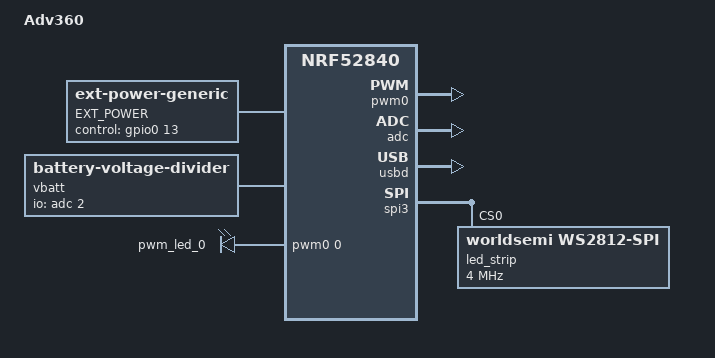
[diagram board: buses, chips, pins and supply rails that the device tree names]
/*
*
* Copyright (c) 2021 Polarity Works
* SPDX-License-Identifier: MIT
*
*/

/dts-v1/;
#include <nordic/nrf52840_qiaa.dtsi>

#include <dt-bindings/led/led.h>
#include <dt-bindings/zmk/matrix_transform.h>

#include "adv360-layouts.dtsi"
#include "adv360_pinctrl.dtsi"

&physical_layout0 {
    transform = <&matrix_transform0>;
};

/ {
    model = "Adv360";
    compatible = "kinesis,adv360";

    chosen {
        zephyr,code-partition = &code_partition;
        zephyr,sram = &sram0;
        zephyr,flash = &flash0;
        zmk,kscan = &kscan0;
        zmk,backlight = &backlight;
        zmk,battery = &vbatt;
        zmk,physical-layout = &physical_layout0;
        zmk,underglow = &led_strip;
    };

    matrix_transform0: keymap_transform_0 {
        compatible = "zmk,matrix-transform";
        columns = <64>;
        rows = <37>;


                    map = <
            RC(4,0) RC(4,1) RC(4,2) RC(4,3) RC(4,4) RC(4,5)  RC(4,6)                                                                        RC(4,13) RC(4,14) RC(4,15) RC(4,16) RC(4,17) RC(4,18) RC(4,19)
            RC(3,0) RC(3,1) RC(3,2) RC(3,3) RC(3,4) RC(3,5)  RC(3,6)                                                                        RC(3,13) RC(3,14) RC(3,15) RC(3,16) RC(3,17) RC(3,18) RC(3,19)
            RC(2,0) RC(2,1) RC(2,2) RC(2,3) RC(2,4) RC(2,5)  RC(2,6)           RC(2,8)  RC(2,9)            RC(2,10) RC(2,11)                RC(2,13) RC(2,14) RC(2,15) RC(2,16) RC(2,17) RC(2,18) RC(2,19)
            RC(1,0) RC(1,1) RC(1,2) RC(1,3) RC(1,4) RC(1,5)                             RC(1,9)            RC(1,10)                                  RC(1,14) RC(1,15) RC(1,16) RC(1,17) RC(1,18) RC(1,19)
            RC(0,0) RC(0,1) RC(0,2) RC(0,3) RC(0,4)                     RC(0,7) RC(0,8) RC(0,9)            RC(0,10) RC(0,11) RC(0,12)                         RC(0,15) RC(0,16) RC(0,17) RC(0,18) RC(0,19)



RC(5,0) RC(5,1) RC(5,2) RC(5,3) RC(5,4) RC(5,5) RC(5,6) RC(5,7) RC(5,8) RC(5,9) RC(5,10) RC(5,11) RC(5,12) RC(5,13) RC(5,14) RC(5,15) RC(5,16) RC(5,17) RC(5,18) RC(5,19) RC(5,20) RC(5,21) RC(5,22) RC(5,23) RC(5,24) RC(5,25) RC(5,26) RC(5,27) RC(5,28) RC(5,29) RC(5,30) RC(5,31) RC(5,32) RC(5,33) RC(5,34) RC(5,35) RC(5,36) RC(5,37) RC(5,38) RC(5,39) RC(5,40) RC(5,41) RC(5,42) RC(5,43) RC(5,44) RC(5,45) RC(5,46) RC(5,47) RC(5,48) RC(5,49) RC(5,50) RC(5,51) RC(5,52) RC(5,53) RC(5,54) RC(5,55) RC(5,56) RC(5,57) RC(5,58) RC(5,59) RC(5,60) RC(5,61) RC(5,62) RC(5,63) 
RC(6,0) RC(6,1) RC(6,2) RC(6,3) RC(6,4) RC(6,5) RC(6,6) RC(6,7) RC(6,8) RC(6,9) RC(6,10) RC(6,11) RC(6,12) RC(6,13) RC(6,14) RC(6,15) RC(6,16) RC(6,17) RC(6,18) RC(6,19) RC(6,20) RC(6,21) RC(6,22) RC(6,23) RC(6,24) RC(6,25) RC(6,26) RC(6,27) RC(6,28) RC(6,29) RC(6,30) RC(6,31) RC(6,32) RC(6,33) RC(6,34) RC(6,35) RC(6,36) RC(6,37) RC(6,38) RC(6,39) RC(6,40) RC(6,41) RC(6,42) RC(6,43) RC(6,44) RC(6,45) RC(6,46) RC(6,47) RC(6,48) RC(6,49) RC(6,50) RC(6,51) RC(6,52) RC(6,53) RC(6,54) RC(6,55) RC(6,56) RC(6,57) RC(6,58) RC(6,59) RC(6,60) RC(6,61) RC(6,62) RC(6,63) 
RC(7,0) RC(7,1) RC(7,2) RC(7,3) RC(7,4) RC(7,5) RC(7,6) RC(7,7) RC(7,8) RC(7,9) RC(7,10) RC(7,11) RC(7,12) RC(7,13) RC(7,14) RC(7,15) RC(7,16) RC(7,17) RC(7,18) RC(7,19) RC(7,20) RC(7,21) RC(7,22) RC(7,23) RC(7,24) RC(7,25) RC(7,26) RC(7,27) RC(7,28) RC(7,29) RC(7,30) RC(7,31) RC(7,32) RC(7,33) RC(7,34) RC(7,35) RC(7,36) RC(7,37) RC(7,38) RC(7,39) RC(7,40) RC(7,41) RC(7,42) RC(7,43) RC(7,44) RC(7,45) RC(7,46) RC(7,47) RC(7,48) RC(7,49) RC(7,50) RC(7,51) RC(7,52) RC(7,53) RC(7,54) RC(7,55) RC(7,56) RC(7,57) RC(7,58) RC(7,59) RC(7,60) RC(7,61) RC(7,62) RC(7,63) 
RC(8,0) RC(8,1) RC(8,2) RC(8,3) RC(8,4) RC(8,5) RC(8,6) RC(8,7) RC(8,8) RC(8,9) RC(8,10) RC(8,11) RC(8,12) RC(8,13) RC(8,14) RC(8,15) RC(8,16) RC(8,17) RC(8,18) RC(8,19) RC(8,20) RC(8,21) RC(8,22) RC(8,23) RC(8,24) RC(8,25) RC(8,26) RC(8,27) RC(8,28) RC(8,29) RC(8,30) RC(8,31) RC(8,32) RC(8,33) RC(8,34) RC(8,35) RC(8,36) RC(8,37) RC(8,38) RC(8,39) RC(8,40) RC(8,41) RC(8,42) RC(8,43) RC(8,44) RC(8,45) RC(8,46) RC(8,47) RC(8,48) RC(8,49) RC(8,50) RC(8,51) RC(8,52) RC(8,53) RC(8,54) RC(8,55) RC(8,56) RC(8,57) RC(8,58) RC(8,59) RC(8,60) RC(8,61) RC(8,62) RC(8,63) 
RC(9,0) RC(9,1) RC(9,2) RC(9,3) RC(9,4) RC(9,5) RC(9,6) RC(9,7) RC(9,8) RC(9,9) RC(9,10) RC(9,11) RC(9,12) RC(9,13) RC(9,14) RC(9,15) RC(9,16) RC(9,17) RC(9,18) RC(9,19) RC(9,20) RC(9,21) RC(9,22) RC(9,23) RC(9,24) RC(9,25) RC(9,26) RC(9,27) RC(9,28) RC(9,29) RC(9,30) RC(9,31) RC(9,32) RC(9,33) RC(9,34) RC(9,35) RC(9,36) RC(9,37) RC(9,38) RC(9,39) RC(9,40) RC(9,41) RC(9,42) RC(9,43) RC(9,44) RC(9,45) RC(9,46) RC(9,47) RC(9,48) RC(9,49) RC(9,50) RC(9,51) RC(9,52) RC(9,53) RC(9,54) RC(9,55) RC(9,56) RC(9,57) RC(9,58) RC(9,59) RC(9,60) RC(9,61) RC(9,62) RC(9,63) 
RC(10,0) RC(10,1) RC(10,2) RC(10,3) RC(10,4) RC(10,5) RC(10,6) RC(10,7) RC(10,8) RC(10,9) RC(10,10) RC(10,11) RC(10,12) RC(10,13) RC(10,14) RC(10,15) RC(10,16) RC(10,17) RC(10,18) RC(10,19) RC(10,20) RC(10,21) RC(10,22) RC(10,23) RC(10,24) RC(10,25) RC(10,26) RC(10,27) RC(10,28) RC(10,29) RC(10,30) RC(10,31) RC(10,32) RC(10,33) RC(10,34) RC(10,35) RC(10,36) RC(10,37) RC(10,38) RC(10,39) RC(10,40) RC(10,41) RC(10,42) RC(10,43) RC(10,44) RC(10,45) RC(10,46) RC(10,47) RC(10,48) RC(10,49) RC(10,50) RC(10,51) RC(10,52) RC(10,53) RC(10,54) RC(10,55) RC(10,56) RC(10,57) RC(10,58) RC(10,59) RC(10,60) RC(10,61) RC(10,62) RC(10,63) 
RC(11,0) RC(11,1) RC(11,2) RC(11,3) RC(11,4) RC(11,5) RC(11,6) RC(11,7) RC(11,8) RC(11,9) RC(11,10) RC(11,11) RC(11,12) RC(11,13) RC(11,14) RC(11,15) RC(11,16) RC(11,17) RC(11,18) RC(11,19) RC(11,20) RC(11,21) RC(11,22) RC(11,23) RC(11,24) RC(11,25) RC(11,26) RC(11,27) RC(11,28) RC(11,29) RC(11,30) RC(11,31) RC(11,32) RC(11,33) RC(11,34) RC(11,35) RC(11,36) RC(11,37) RC(11,38) RC(11,39) RC(11,40) RC(11,41) RC(11,42) RC(11,43) RC(11,44) RC(11,45) RC(11,46) RC(11,47) RC(11,48) RC(11,49) RC(11,50) RC(11,51) RC(11,52) RC(11,53) RC(11,54) RC(11,55) RC(11,56) RC(11,57) RC(11,58) RC(11,59) RC(11,60) RC(11,61) RC(11,62) RC(11,63) 
RC(12,0) RC(12,1) RC(12,2) RC(12,3) RC(12,4) RC(12,5) RC(12,6) RC(12,7) RC(12,8) RC(12,9) RC(12,10) RC(12,11) RC(12,12) RC(12,13) RC(12,14) RC(12,15) RC(12,16) RC(12,17) RC(12,18) RC(12,19) RC(12,20) RC(12,21) RC(12,22) RC(12,23) RC(12,24) RC(12,25) RC(12,26) RC(12,27) RC(12,28) RC(12,29) RC(12,30) RC(12,31) RC(12,32) RC(12,33) RC(12,34) RC(12,35) RC(12,36) RC(12,37) RC(12,38) RC(12,39) RC(12,40) RC(12,41) RC(12,42) RC(12,43) RC(12,44) RC(12,45) RC(12,46) RC(12,47) RC(12,48) RC(12,49) RC(12,50) RC(12,51) RC(12,52) RC(12,53) RC(12,54) RC(12,55) RC(12,56) RC(12,57) RC(12,58) RC(12,59) RC(12,60) RC(12,61) RC(12,62) RC(12,63) 
RC(13,0) RC(13,1) RC(13,2) RC(13,3) RC(13,4) RC(13,5) RC(13,6) RC(13,7) RC(13,8) RC(13,9) RC(13,10) RC(13,11) RC(13,12) RC(13,13) RC(13,14) RC(13,15) RC(13,16) RC(13,17) RC(13,18) RC(13,19) RC(13,20) RC(13,21) RC(13,22) RC(13,23) RC(13,24) RC(13,25) RC(13,26) RC(13,27) RC(13,28) RC(13,29) RC(13,30) RC(13,31) RC(13,32) RC(13,33) RC(13,34) RC(13,35) RC(13,36) RC(13,37) RC(13,38) RC(13,39) RC(13,40) RC(13,41) RC(13,42) RC(13,43) RC(13,44) RC(13,45) RC(13,46) RC(13,47) RC(13,48) RC(13,49) RC(13,50) RC(13,51) RC(13,52) RC(13,53) RC(13,54) RC(13,55) RC(13,56) RC(13,57) RC(13,58) RC(13,59) RC(13,60) RC(13,61) RC(13,62) RC(13,63) 
RC(14,0) RC(14,1) RC(14,2) RC(14,3) RC(14,4) RC(14,5) RC(14,6) RC(14,7) RC(14,8) RC(14,9) RC(14,10) RC(14,11) RC(14,12) RC(14,13) RC(14,14) RC(14,15) RC(14,16) RC(14,17) RC(14,18) RC(14,19) RC(14,20) RC(14,21) RC(14,22) RC(14,23) RC(14,24) RC(14,25) RC(14,26) RC(14,27) RC(14,28) RC(14,29) RC(14,30) RC(14,31) RC(14,32) RC(14,33) RC(14,34) RC(14,35) RC(14,36) RC(14,37) RC(14,38) RC(14,39) RC(14,40) RC(14,41) RC(14,42) RC(14,43) RC(14,44) RC(14,45) RC(14,46) RC(14,47) RC(14,48) RC(14,49) RC(14,50) RC(14,51) RC(14,52) RC(14,53) RC(14,54) RC(14,55) RC(14,56) RC(14,57) RC(14,58) RC(14,59) RC(14,60) RC(14,61) RC(14,62) RC(14,63) 
RC(15,0) RC(15,1) RC(15,2) RC(15,3) RC(15,4) RC(15,5) RC(15,6) RC(15,7) RC(15,8) RC(15,9) RC(15,10) RC(15,11) RC(15,12) RC(15,13) RC(15,14) RC(15,15) RC(15,16) RC(15,17) RC(15,18) RC(15,19) RC(15,20) RC(15,21) RC(15,22) RC(15,23) RC(15,24) RC(15,25) RC(15,26) RC(15,27) RC(15,28) RC(15,29) RC(15,30) RC(15,31) RC(15,32) RC(15,33) RC(15,34) RC(15,35) RC(15,36) RC(15,37) RC(15,38) RC(15,39) RC(15,40) RC(15,41) RC(15,42) RC(15,43) RC(15,44) RC(15,45) RC(15,46) RC(15,47) RC(15,48) RC(15,49) RC(15,50) RC(15,51) RC(15,52) RC(15,53) RC(15,54) RC(15,55) RC(15,56) RC(15,57) RC(15,58) RC(15,59) RC(15,60) RC(15,61) RC(15,62) RC(15,63) 
RC(16,0) RC(16,1) RC(16,2) RC(16,3) RC(16,4) RC(16,5) RC(16,6) RC(16,7) RC(16,8) RC(16,9) RC(16,10) RC(16,11) RC(16,12) RC(16,13) RC(16,14) RC(16,15) RC(16,16) RC(16,17) RC(16,18) RC(16,19) RC(16,20) RC(16,21) RC(16,22) RC(16,23) RC(16,24) RC(16,25) RC(16,26) RC(16,27) RC(16,28) RC(16,29) RC(16,30) RC(16,31) RC(16,32) RC(16,33) RC(16,34) RC(16,35) RC(16,36) RC(16,37) RC(16,38) RC(16,39) RC(16,40) RC(16,41) RC(16,42) RC(16,43) RC(16,44) RC(16,45) RC(16,46) RC(16,47) RC(16,48) RC(16,49) RC(16,50) RC(16,51) RC(16,52) RC(16,53) RC(16,54) RC(16,55) RC(16,56) RC(16,57) RC(16,58) RC(16,59) RC(16,60) RC(16,61) RC(16,62) RC(16,63) 
RC(17,0) RC(17,1) RC(17,2) RC(17,3) RC(17,4) RC(17,5) RC(17,6) RC(17,7) RC(17,8) RC(17,9) RC(17,10) RC(17,11) RC(17,12) RC(17,13) RC(17,14) RC(17,15) RC(17,16) RC(17,17) RC(17,18) RC(17,19) RC(17,20) RC(17,21) RC(17,22) RC(17,23) RC(17,24) RC(17,25) RC(17,26) RC(17,27) RC(17,28) RC(17,29) RC(17,30) RC(17,31) RC(17,32) RC(17,33) RC(17,34) RC(17,35) RC(17,36) RC(17,37) RC(17,38) RC(17,39) RC(17,40) RC(17,41) RC(17,42) RC(17,43) RC(17,44) RC(17,45) RC(17,46) RC(17,47) RC(17,48) RC(17,49) RC(17,50) RC(17,51) RC(17,52) RC(17,53) RC(17,54) RC(17,55) RC(17,56) RC(17,57) RC(17,58) RC(17,59) RC(17,60) RC(17,61) RC(17,62) RC(17,63) 
RC(18,0) RC(18,1) RC(18,2) RC(18,3) RC(18,4) RC(18,5) RC(18,6) RC(18,7) RC(18,8) RC(18,9) RC(18,10) RC(18,11) RC(18,12) RC(18,13) RC(18,14) RC(18,15) RC(18,16) RC(18,17) RC(18,18) RC(18,19) RC(18,20) RC(18,21) RC(18,22) RC(18,23) RC(18,24) RC(18,25) RC(18,26) RC(18,27) RC(18,28) RC(18,29) RC(18,30) RC(18,31) RC(18,32) RC(18,33) RC(18,34) RC(18,35) RC(18,36) RC(18,37) RC(18,38) RC(18,39) RC(18,40) RC(18,41) RC(18,42) RC(18,43) RC(18,44) RC(18,45) RC(18,46) RC(18,47) RC(18,48) RC(18,49) RC(18,50) RC(18,51) RC(18,52) RC(18,53) RC(18,54) RC(18,55) RC(18,56) RC(18,57) RC(18,58) RC(18,59) RC(18,60) RC(18,61) RC(18,62) RC(18,63) 
RC(19,0) RC(19,1) RC(19,2) RC(19,3) RC(19,4) RC(19,5) RC(19,6) RC(19,7) RC(19,8) RC(19,9) RC(19,10) RC(19,11) RC(19,12) RC(19,13) RC(19,14) RC(19,15) RC(19,16) RC(19,17) RC(19,18) RC(19,19) RC(19,20) RC(19,21) RC(19,22) RC(19,23) RC(19,24) RC(19,25) RC(19,26) RC(19,27) RC(19,28) RC(19,29) RC(19,30) RC(19,31) RC(19,32) RC(19,33) RC(19,34) RC(19,35) RC(19,36) RC(19,37) RC(19,38) RC(19,39) RC(19,40) RC(19,41) RC(19,42) RC(19,43) RC(19,44) RC(19,45) RC(19,46) RC(19,47) RC(19,48) RC(19,49) RC(19,50) RC(19,51) RC(19,52) RC(19,53) RC(19,54) RC(19,55) RC(19,56) RC(19,57) RC(19,58) RC(19,59) RC(19,60) RC(19,61) RC(19,62) RC(19,63) 
RC(20,0) RC(20,1) RC(20,2) RC(20,3) RC(20,4) RC(20,5) RC(20,6) RC(20,7) RC(20,8) RC(20,9) RC(20,10) RC(20,11) RC(20,12) RC(20,13) RC(20,14) RC(20,15) RC(20,16) RC(20,17) RC(20,18) RC(20,19) RC(20,20) RC(20,21) RC(20,22) RC(20,23) RC(20,24) RC(20,25) RC(20,26) RC(20,27) RC(20,28) RC(20,29) RC(20,30) RC(20,31) RC(20,32) RC(20,33) RC(20,34) RC(20,35) RC(20,36) RC(20,37) RC(20,38) RC(20,39) RC(20,40) RC(20,41) RC(20,42) RC(20,43) RC(20,44) RC(20,45) RC(20,46) RC(20,47) RC(20,48) RC(20,49) RC(20,50) RC(20,51) RC(20,52) RC(20,53) RC(20,54) RC(20,55) RC(20,56) RC(20,57) RC(20,58) RC(20,59) RC(20,60) RC(20,61) RC(20,62) RC(20,63) 
RC(21,0) RC(21,1) RC(21,2) RC(21,3) RC(21,4) RC(21,5) RC(21,6) RC(21,7) RC(21,8) RC(21,9) RC(21,10) RC(21,11) RC(21,12) RC(21,13) RC(21,14) RC(21,15) RC(21,16) RC(21,17) RC(21,18) RC(21,19) RC(21,20) RC(21,21) RC(21,22) RC(21,23) RC(21,24) RC(21,25) RC(21,26) RC(21,27) RC(21,28) RC(21,29) RC(21,30) RC(21,31) RC(21,32) RC(21,33) RC(21,34) RC(21,35) RC(21,36) RC(21,37) RC(21,38) RC(21,39) RC(21,40) RC(21,41) RC(21,42) RC(21,43) RC(21,44) RC(21,45) RC(21,46) RC(21,47) RC(21,48) RC(21,49) RC(21,50) RC(21,51) RC(21,52) RC(21,53) RC(21,54) RC(21,55) RC(21,56) RC(21,57) RC(21,58) RC(21,59) RC(21,60) RC(21,61) RC(21,62) RC(21,63) 
RC(22,0) RC(22,1) RC(22,2) RC(22,3) RC(22,4) RC(22,5) RC(22,6) RC(22,7) RC(22,8) RC(22,9) RC(22,10) RC(22,11) RC(22,12) RC(22,13) RC(22,14) RC(22,15) RC(22,16) RC(22,17) RC(22,18) RC(22,19) RC(22,20) RC(22,21) RC(22,22) RC(22,23) RC(22,24) RC(22,25) RC(22,26) RC(22,27) RC(22,28) RC(22,29) RC(22,30) RC(22,31) RC(22,32) RC(22,33) RC(22,34) RC(22,35) RC(22,36) RC(22,37) RC(22,38) RC(22,39) RC(22,40) RC(22,41) RC(22,42) RC(22,43) RC(22,44) RC(22,45) RC(22,46) RC(22,47) RC(22,48) RC(22,49) RC(22,50) RC(22,51) RC(22,52) RC(22,53) RC(22,54) RC(22,55) RC(22,56) RC(22,57) RC(22,58) RC(22,59) RC(22,60) RC(22,61) RC(22,62) RC(22,63) 
RC(23,0) RC(23,1) RC(23,2) RC(23,3) RC(23,4) RC(23,5) RC(23,6) RC(23,7) RC(23,8) RC(23,9) RC(23,10) RC(23,11) RC(23,12) RC(23,13) RC(23,14) RC(23,15) RC(23,16) RC(23,17) RC(23,18) RC(23,19) RC(23,20) RC(23,21) RC(23,22) RC(23,23) RC(23,24) RC(23,25) RC(23,26) RC(23,27) RC(23,28) RC(23,29) RC(23,30) RC(23,31) RC(23,32) RC(23,33) RC(23,34) RC(23,35) RC(23,36) RC(23,37) RC(23,38) RC(23,39) RC(23,40) RC(23,41) RC(23,42) RC(23,43) RC(23,44) RC(23,45) RC(23,46) RC(23,47) RC(23,48) RC(23,49) RC(23,50) RC(23,51) RC(23,52) RC(23,53) RC(23,54) RC(23,55) RC(23,56) RC(23,57) RC(23,58) RC(23,59) RC(23,60) RC(23,61) RC(23,62) RC(23,63) 
RC(24,0) RC(24,1) RC(24,2) RC(24,3) RC(24,4) RC(24,5) RC(24,6) RC(24,7) RC(24,8) RC(24,9) RC(24,10) RC(24,11) RC(24,12) RC(24,13) RC(24,14) RC(24,15) RC(24,16) RC(24,17) RC(24,18) RC(24,19) RC(24,20) RC(24,21) RC(24,22) RC(24,23) RC(24,24) RC(24,25) RC(24,26) RC(24,27) RC(24,28) RC(24,29) RC(24,30) RC(24,31) RC(24,32) RC(24,33) RC(24,34) RC(24,35) RC(24,36) RC(24,37) RC(24,38) RC(24,39) RC(24,40) RC(24,41) RC(24,42) RC(24,43) RC(24,44) RC(24,45) RC(24,46) RC(24,47) RC(24,48) RC(24,49) RC(24,50) RC(24,51) RC(24,52) RC(24,53) RC(24,54) RC(24,55) RC(24,56) RC(24,57) RC(24,58) RC(24,59) RC(24,60) RC(24,61) RC(24,62) RC(24,63) 
RC(25,0) RC(25,1) RC(25,2) RC(25,3) RC(25,4) RC(25,5) RC(25,6) RC(25,7) RC(25,8) RC(25,9) RC(25,10) RC(25,11) RC(25,12) RC(25,13) RC(25,14) RC(25,15) RC(25,16) RC(25,17) RC(25,18) RC(25,19) RC(25,20) RC(25,21) RC(25,22) RC(25,23) RC(25,24) RC(25,25) RC(25,26) RC(25,27) RC(25,28) RC(25,29) RC(25,30) RC(25,31) RC(25,32) RC(25,33) RC(25,34) RC(25,35) RC(25,36) RC(25,37) RC(25,38) RC(25,39) RC(25,40) RC(25,41) RC(25,42) RC(25,43) RC(25,44) RC(25,45) RC(25,46) RC(25,47) RC(25,48) RC(25,49) RC(25,50) RC(25,51) RC(25,52) RC(25,53) RC(25,54) RC(25,55) RC(25,56) RC(25,57) RC(25,58) RC(25,59) RC(25,60) RC(25,61) RC(25,62) RC(25,63) 
RC(26,0) RC(26,1) RC(26,2) RC(26,3) RC(26,4) RC(26,5) RC(26,6) RC(26,7) RC(26,8) RC(26,9) RC(26,10) RC(26,11) RC(26,12) RC(26,13) RC(26,14) RC(26,15) RC(26,16) RC(26,17) RC(26,18) RC(26,19) RC(26,20) RC(26,21) RC(26,22) RC(26,23) RC(26,24) RC(26,25) RC(26,26) RC(26,27) RC(26,28) RC(26,29) RC(26,30) RC(26,31) RC(26,32) RC(26,33) RC(26,34) RC(26,35) RC(26,36) RC(26,37) RC(26,38) RC(26,39) RC(26,40) RC(26,41) RC(26,42) RC(26,43) RC(26,44) RC(26,45) RC(26,46) RC(26,47) RC(26,48) RC(26,49) RC(26,50) RC(26,51) RC(26,52) RC(26,53) RC(26,54) RC(26,55) RC(26,56) RC(26,57) RC(26,58) RC(26,59) RC(26,60) RC(26,61) RC(26,62) RC(26,63) 
RC(27,0) RC(27,1) RC(27,2) RC(27,3) RC(27,4) RC(27,5) RC(27,6) RC(27,7) RC(27,8) RC(27,9) RC(27,10) RC(27,11) RC(27,12) RC(27,13) RC(27,14) RC(27,15) RC(27,16) RC(27,17) RC(27,18) RC(27,19) RC(27,20) RC(27,21) RC(27,22) RC(27,23) RC(27,24) RC(27,25) RC(27,26) RC(27,27) RC(27,28) RC(27,29) RC(27,30) RC(27,31) RC(27,32) RC(27,33) RC(27,34) RC(27,35) RC(27,36) RC(27,37) RC(27,38) RC(27,39) RC(27,40) RC(27,41) RC(27,42) RC(27,43) RC(27,44) RC(27,45) RC(27,46) RC(27,47) RC(27,48) RC(27,49) RC(27,50) RC(27,51) RC(27,52) RC(27,53) RC(27,54) RC(27,55) RC(27,56) RC(27,57) RC(27,58) RC(27,59) RC(27,60) RC(27,61) RC(27,62) RC(27,63) 
RC(28,0) RC(28,1) RC(28,2) RC(28,3) RC(28,4) RC(28,5) RC(28,6) RC(28,7) RC(28,8) RC(28,9) RC(28,10) RC(28,11) RC(28,12) RC(28,13) RC(28,14) RC(28,15) RC(28,16) RC(28,17) RC(28,18) RC(28,19) RC(28,20) RC(28,21) RC(28,22) RC(28,23) RC(28,24) RC(28,25) RC(28,26) RC(28,27) RC(28,28) RC(28,29) RC(28,30) RC(28,31) RC(28,32) RC(28,33) RC(28,34) RC(28,35) RC(28,36) RC(28,37) RC(28,38) RC(28,39) RC(28,40) RC(28,41) RC(28,42) RC(28,43) RC(28,44) RC(28,45) RC(28,46) RC(28,47) RC(28,48) RC(28,49) RC(28,50) RC(28,51) RC(28,52) RC(28,53) RC(28,54) RC(28,55) RC(28,56) RC(28,57) RC(28,58) RC(28,59) RC(28,60) RC(28,61) RC(28,62) RC(28,63) 
RC(29,0) RC(29,1) RC(29,2) RC(29,3) RC(29,4) RC(29,5) RC(29,6) RC(29,7) RC(29,8) RC(29,9) RC(29,10) RC(29,11) RC(29,12) RC(29,13) RC(29,14) RC(29,15) RC(29,16) RC(29,17) RC(29,18) RC(29,19) RC(29,20) RC(29,21) RC(29,22) RC(29,23) RC(29,24) RC(29,25) RC(29,26) RC(29,27) RC(29,28) RC(29,29) RC(29,30) RC(29,31) RC(29,32) RC(29,33) RC(29,34) RC(29,35) RC(29,36) RC(29,37) RC(29,38) RC(29,39) RC(29,40) RC(29,41) RC(29,42) RC(29,43) RC(29,44) RC(29,45) RC(29,46) RC(29,47) RC(29,48) RC(29,49) RC(29,50) RC(29,51) RC(29,52) RC(29,53) RC(29,54) RC(29,55) RC(29,56) RC(29,57) RC(29,58) RC(29,59) RC(29,60) RC(29,61) RC(29,62) RC(29,63) 
RC(30,0) RC(30,1) RC(30,2) RC(30,3) RC(30,4) RC(30,5) RC(30,6) RC(30,7) RC(30,8) RC(30,9) RC(30,10) RC(30,11) RC(30,12) RC(30,13) RC(30,14) RC(30,15) RC(30,16) RC(30,17) RC(30,18) RC(30,19) RC(30,20) RC(30,21) RC(30,22) RC(30,23) RC(30,24) RC(30,25) RC(30,26) RC(30,27) RC(30,28) RC(30,29) RC(30,30) RC(30,31) RC(30,32) RC(30,33) RC(30,34) RC(30,35) RC(30,36) RC(30,37) RC(30,38) RC(30,39) RC(30,40) RC(30,41) RC(30,42) RC(30,43) RC(30,44) RC(30,45) RC(30,46) RC(30,47) RC(30,48) RC(30,49) RC(30,50) RC(30,51) RC(30,52) RC(30,53) RC(30,54) RC(30,55) RC(30,56) RC(30,57) RC(30,58) RC(30,59) RC(30,60) RC(30,61) RC(30,62) RC(30,63) 
RC(31,0) RC(31,1) RC(31,2) RC(31,3) RC(31,4) RC(31,5) RC(31,6) RC(31,7) RC(31,8) RC(31,9) RC(31,10) RC(31,11) RC(31,12) RC(31,13) RC(31,14) RC(31,15) RC(31,16) RC(31,17) RC(31,18) RC(31,19) RC(31,20) RC(31,21) RC(31,22) RC(31,23) RC(31,24) RC(31,25) RC(31,26) RC(31,27) RC(31,28) RC(31,29) RC(31,30) RC(31,31) RC(31,32) RC(31,33) RC(31,34) RC(31,35) RC(31,36) RC(31,37) RC(31,38) RC(31,39) RC(31,40) RC(31,41) RC(31,42) RC(31,43) RC(31,44) RC(31,45) RC(31,46) RC(31,47) RC(31,48) RC(31,49) RC(31,50) RC(31,51) RC(31,52) RC(31,53) RC(31,54) RC(31,55) RC(31,56) RC(31,57) RC(31,58) RC(31,59) RC(31,60) RC(31,61) RC(31,62) RC(31,63) 
RC(32,0) RC(32,1) RC(32,2) RC(32,3) RC(32,4) RC(32,5) RC(32,6) RC(32,7) RC(32,8) RC(32,9) RC(32,10) RC(32,11) RC(32,12) RC(32,13) RC(32,14) RC(32,15) RC(32,16) RC(32,17) RC(32,18) RC(32,19) RC(32,20) RC(32,21) RC(32,22) RC(32,23) RC(32,24) RC(32,25) RC(32,26) RC(32,27) RC(32,28) RC(32,29) RC(32,30) RC(32,31) RC(32,32) RC(32,33) RC(32,34) RC(32,35) RC(32,36) RC(32,37) RC(32,38) RC(32,39) RC(32,40) RC(32,41) RC(32,42) RC(32,43) RC(32,44) RC(32,45) RC(32,46) RC(32,47) RC(32,48) RC(32,49) RC(32,50) RC(32,51) RC(32,52) RC(32,53) RC(32,54) RC(32,55) RC(32,56) RC(32,57) RC(32,58) RC(32,59) RC(32,60) RC(32,61) RC(32,62) RC(32,63) 
RC(33,0) RC(33,1) RC(33,2) RC(33,3) RC(33,4) RC(33,5) RC(33,6) RC(33,7) RC(33,8) RC(33,9) RC(33,10) RC(33,11) RC(33,12) RC(33,13) RC(33,14) RC(33,15) RC(33,16) RC(33,17) RC(33,18) RC(33,19) RC(33,20) RC(33,21) RC(33,22) RC(33,23) RC(33,24) RC(33,25) RC(33,26) RC(33,27) RC(33,28) RC(33,29) RC(33,30) RC(33,31) RC(33,32) RC(33,33) RC(33,34) RC(33,35) RC(33,36) RC(33,37) RC(33,38) RC(33,39) RC(33,40) RC(33,41) RC(33,42) RC(33,43) RC(33,44) RC(33,45) RC(33,46) RC(33,47) RC(33,48) RC(33,49) RC(33,50) RC(33,51) RC(33,52) RC(33,53) RC(33,54) RC(33,55) RC(33,56) RC(33,57) RC(33,58) RC(33,59) RC(33,60) RC(33,61) RC(33,62) RC(33,63) 
RC(34,0) RC(34,1) RC(34,2) RC(34,3) RC(34,4) RC(34,5) RC(34,6) RC(34,7) RC(34,8) RC(34,9) RC(34,10) RC(34,11) RC(34,12) RC(34,13) RC(34,14) RC(34,15) RC(34,16) RC(34,17) RC(34,18) RC(34,19) RC(34,20) RC(34,21) RC(34,22) RC(34,23) RC(34,24) RC(34,25) RC(34,26) RC(34,27) RC(34,28) RC(34,29) RC(34,30) RC(34,31) RC(34,32) RC(34,33) RC(34,34) RC(34,35) RC(34,36) RC(34,37) RC(34,38) RC(34,39) RC(34,40) RC(34,41) RC(34,42) RC(34,43) RC(34,44) RC(34,45) RC(34,46) RC(34,47) RC(34,48) RC(34,49) RC(34,50) RC(34,51) RC(34,52) RC(34,53) RC(34,54) RC(34,55) RC(34,56) RC(34,57) RC(34,58) RC(34,59) RC(34,60) RC(34,61) RC(34,62) RC(34,63) 
RC(35,0) RC(35,1) RC(35,2) RC(35,3) RC(35,4) RC(35,5) RC(35,6) RC(35,7) RC(35,8) RC(35,9) RC(35,10) RC(35,11) RC(35,12) RC(35,13) RC(35,14) RC(35,15) RC(35,16) RC(35,17) RC(35,18) RC(35,19) RC(35,20) RC(35,21) RC(35,22) RC(35,23) RC(35,24) RC(35,25) RC(35,26) RC(35,27) RC(35,28) RC(35,29) RC(35,30) RC(35,31) RC(35,32) RC(35,33) RC(35,34) RC(35,35) RC(35,36) RC(35,37) RC(35,38) RC(35,39) RC(35,40) RC(35,41) RC(35,42) RC(35,43) RC(35,44) RC(35,45) RC(35,46) RC(35,47) RC(35,48) RC(35,49) RC(35,50) RC(35,51) RC(35,52) RC(35,53) RC(35,54) RC(35,55) RC(35,56) RC(35,57) RC(35,58) RC(35,59) RC(35,60) RC(35,61) RC(35,62) RC(35,63) 
RC(36,0) RC(36,1) RC(36,2) RC(36,3) RC(36,4) RC(36,5) RC(36,6) RC(36,7) RC(36,8) RC(36,9) RC(36,10) RC(36,11) RC(36,12) RC(36,13) RC(36,14) RC(36,15) RC(36,16) RC(36,17) RC(36,18) RC(36,19) RC(36,20) RC(36,21) RC(36,22) RC(36,23) RC(36,24) RC(36,25) RC(36,26) RC(36,27) RC(36,28) RC(36,29) RC(36,30) RC(36,31) RC(36,32) RC(36,33) RC(36,34) RC(36,35) RC(36,36) RC(36,37) RC(36,38) RC(36,39) RC(36,40) RC(36,41) RC(36,42) RC(36,43) RC(36,44) RC(36,45) RC(36,46) RC(36,47) RC(36,48) RC(36,49) RC(36,50) RC(36,51) RC(36,52) RC(36,53) RC(36,54) RC(36,55) RC(36,56) RC(36,57) RC(36,58) RC(36,59) RC(36,60) RC(36,61) RC(36,62) RC(36,63) 



        >;
    };
    EXT_POWER {
            compatible = "zmk,ext-power-generic";
            control-gpios = <&gpio0 13 GPIO_ACTIVE_HIGH>;
        };

    vbatt: vbatt {
        compatible = "zmk,battery-voltage-divider";
        io-channels = <&adc 2>;
        output-ohms = <100000>;
        full-ohms = <(100000 + 100000)>;
    };

    backlight: pwmleds {
            compatible = "pwm-leds";
            pwm_led_0 {
                pwms = <&pwm0 0 10000 PWM_POLARITY_NORMAL>;
            };
        };

};

&pwm0 {
    status = "okay";
    pinctrl-0 = <&pwm0_default>;
    pinctrl-1 = <&pwm0_sleep>;
    pinctrl-names = "default", "sleep";
};

&adc {
    status = "okay";
};

&gpiote {
    status = "okay";
};

&gpio0 {
    status = "okay";
};

&gpio1 {
    status = "okay";
};

zephyr_udc0: &usbd {
    status = "okay";
};


&flash0 {
    /*
     * For more information, see:
     * http://docs.zephyrproject.org/latest/devices/dts/flash_partitions.html
     */
    partitions {
        compatible = "fixed-partitions";
        #address-cells = <1>;
        #size-cells = <1>;

        sd_partition: partition@0 {
            reg = <0x00000000 0x00026000>;
        };
        code_partition: partition@26000 {
            reg = <0x00026000 0x000c6000>;
        };

        /*
         * The flash starting at 0x000ec000 and ending at
         * 0x000f3fff is reserved for use by the application.
         */

        /*
         * Storage partition will be used by FCB/LittleFS/NVS
         * if enabled.
         */
        storage_partition: partition@ec000 {
            reg = <0x000ec000 0x00008000>;
        };

        boot_partition: partition@f4000 {
            reg = <0x000f4000 0x0000c000>;
        };
    };
};

&spi3 {
    compatible = "nordic,nrf-spim";
    status = "okay";
    pinctrl-0 = <&spi3_default>;
    pinctrl-1 = <&spi3_sleep>;
    pinctrl-names = "default", "sleep";

    led_strip: ws2812@0 {
        compatible = "worldsemi,ws2812-spi";

        /* SPI */
        reg = <0>;
        spi-max-frequency = <4000000>;

        /* WS2812 */
        chain-length = <3>; /* number of LEDs */
        spi-one-frame = <0x70>;
        spi-zero-frame = <0x40>;

        color-mapping = <LED_COLOR_ID_GREEN
                   LED_COLOR_ID_RED
                   LED_COLOR_ID_BLUE>;
    };
};
